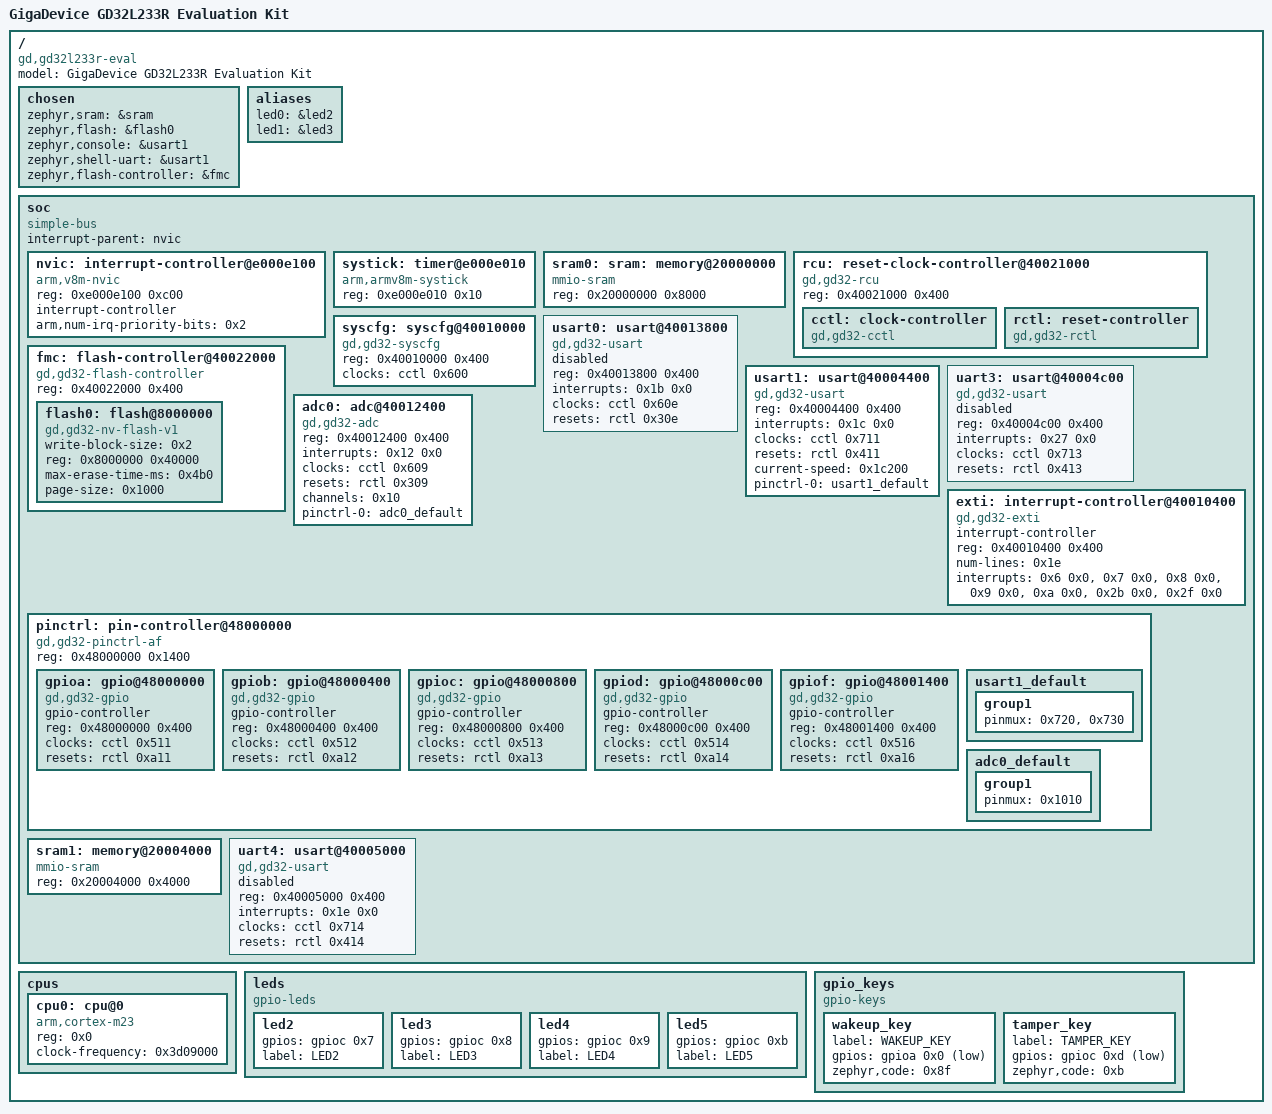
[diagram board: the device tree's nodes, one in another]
/dts-v1/;

/* node '/' defined in zephyr/dts/common/skeleton.dtsi:9 */
/ {
	#address-cells = < 0x1 >;                      /* in zephyr/dts/common/skeleton.dtsi:10 */
	#size-cells = < 0x1 >;                         /* in zephyr/dts/common/skeleton.dtsi:11 */
	model = "GigaDevice GD32L233R Evaluation Kit"; /* in zephyr/boards/gd/gd32l233r_eval/gd32l233r_eval.dts:13 */
	compatible = "gd,gd32l233r-eval";              /* in zephyr/boards/gd/gd32l233r_eval/gd32l233r_eval.dts:14 */

	/* node '/chosen' defined in zephyr/dts/common/skeleton.dtsi:13 */
	chosen {
		zephyr,sram = &sram;            /* in zephyr/boards/gd/gd32l233r_eval/gd32l233r_eval.dts:17 */
		zephyr,flash = &flash0;         /* in zephyr/boards/gd/gd32l233r_eval/gd32l233r_eval.dts:18 */
		zephyr,console = &usart1;       /* in zephyr/boards/gd/gd32l233r_eval/gd32l233r_eval.dts:19 */
		zephyr,shell-uart = &usart1;    /* in zephyr/boards/gd/gd32l233r_eval/gd32l233r_eval.dts:20 */
		zephyr,flash-controller = &fmc; /* in zephyr/boards/gd/gd32l233r_eval/gd32l233r_eval.dts:21 */
	};

	/* node '/aliases' defined in zephyr/dts/common/skeleton.dtsi:15 */
	aliases {
		led0 = &led2; /* in zephyr/boards/gd/gd32l233r_eval/gd32l233r_eval.dts:65 */
		led1 = &led3; /* in zephyr/boards/gd/gd32l233r_eval/gd32l233r_eval.dts:66 */
	};

	/* node '/soc' defined in zephyr/dts/arm/armv8-m.dtsi:6 */
	soc {
		#address-cells = < 0x1 >;     /* in zephyr/dts/arm/armv8-m.dtsi:7 */
		#size-cells = < 0x1 >;        /* in zephyr/dts/arm/armv8-m.dtsi:8 */
		compatible = "simple-bus";    /* in zephyr/dts/arm/armv8-m.dtsi:9 */
		interrupt-parent = < &nvic >; /* in zephyr/dts/arm/armv8-m.dtsi:10 */
		ranges;                       /* in zephyr/dts/arm/armv8-m.dtsi:11 */

		/* node '/soc/interrupt-controller@e000e100' defined in zephyr/dts/arm/armv8-m.dtsi:13 */
		nvic: interrupt-controller@e000e100 {
			#address-cells = < 0x1 >;            /* in zephyr/dts/arm/armv8-m.dtsi:14 */
			compatible = "arm,v8m-nvic";         /* in zephyr/dts/arm/armv8-m.dtsi:15 */
			reg = < 0xe000e100 0xc00 >;          /* in zephyr/dts/arm/armv8-m.dtsi:16 */
			interrupt-controller;                /* in zephyr/dts/arm/armv8-m.dtsi:17 */
			#interrupt-cells = < 0x2 >;          /* in zephyr/dts/arm/armv8-m.dtsi:18 */
			arm,num-irq-priority-bits = < 0x2 >; /* in zephyr/dts/arm/gd/gd32l23x/gd32l23x.dtsi:181 */
			phandle = < 0x1 >;                   /* in zephyr/dts/arm/armv8-m.dtsi:10 */
		};

		/* node '/soc/timer@e000e010' defined in zephyr/dts/arm/armv8-m.dtsi:21 */
		systick: timer@e000e010 {
			compatible = "arm,armv8m-systick"; /* in zephyr/dts/arm/armv8-m.dtsi:22 */
			reg = < 0xe000e010 0x10 >;         /* in zephyr/dts/arm/armv8-m.dtsi:23 */
		};

		/* node '/soc/memory@20000000' defined in zephyr/dts/arm/gd/gd32l23x/gd32l23x.dtsi:27 */
		sram0: sram: memory@20000000 {
			compatible = "mmio-sram";    /* in zephyr/dts/arm/gd/gd32l23x/gd32l233rc.dtsi:19 */
			reg = < 0x20000000 0x8000 >; /* in zephyr/dts/arm/gd/gd32l23x/gd32l233rc.dtsi:20 */
		};

		/* node '/soc/reset-clock-controller@40021000' defined in zephyr/dts/arm/gd/gd32l23x/gd32l23x.dtsi:32 */
		rcu: reset-clock-controller@40021000 {
			compatible = "gd,gd32-rcu"; /* in zephyr/dts/arm/gd/gd32l23x/gd32l23x.dtsi:33 */
			reg = < 0x40021000 0x400 >; /* in zephyr/dts/arm/gd/gd32l23x/gd32l23x.dtsi:34 */
			status = "okay";            /* in zephyr/dts/arm/gd/gd32l23x/gd32l23x.dtsi:35 */

			/* node '/soc/reset-clock-controller@40021000/clock-controller' defined in zephyr/dts/arm/gd/gd32l23x/gd32l23x.dtsi:37 */
			cctl: clock-controller {
				compatible = "gd,gd32-cctl"; /* in zephyr/dts/arm/gd/gd32l23x/gd32l23x.dtsi:38 */
				#clock-cells = < 0x1 >;      /* in zephyr/dts/arm/gd/gd32l23x/gd32l23x.dtsi:39 */
				status = "okay";             /* in zephyr/dts/arm/gd/gd32l23x/gd32l23x.dtsi:40 */
				phandle = < 0x2 >;           /* in zephyr/dts/arm/gd/gd32l23x/gd32l23x.dtsi:53 */
			};

			/* node '/soc/reset-clock-controller@40021000/reset-controller' defined in zephyr/dts/arm/gd/gd32l23x/gd32l23x.dtsi:43 */
			rctl: reset-controller {
				compatible = "gd,gd32-rctl"; /* in zephyr/dts/arm/gd/gd32l23x/gd32l23x.dtsi:44 */
				#reset-cells = < 0x1 >;      /* in zephyr/dts/arm/gd/gd32l23x/gd32l23x.dtsi:45 */
				status = "okay";             /* in zephyr/dts/arm/gd/gd32l23x/gd32l23x.dtsi:46 */
				phandle = < 0x3 >;           /* in zephyr/dts/arm/gd/gd32l23x/gd32l23x.dtsi:74 */
			};
		};

		/* node '/soc/syscfg@40010000' defined in zephyr/dts/arm/gd/gd32l23x/gd32l23x.dtsi:50 */
		syscfg: syscfg@40010000 {
			compatible = "gd,gd32-syscfg"; /* in zephyr/dts/arm/gd/gd32l23x/gd32l23x.dtsi:51 */
			reg = < 0x40010000 0x400 >;    /* in zephyr/dts/arm/gd/gd32l23x/gd32l23x.dtsi:52 */
			clocks = < &cctl 0x600 >;      /* in zephyr/dts/arm/gd/gd32l23x/gd32l23x.dtsi:53 */
		};

		/* node '/soc/flash-controller@40022000' defined in zephyr/dts/arm/gd/gd32l23x/gd32l23x.dtsi:56 */
		fmc: flash-controller@40022000 {
			compatible = "gd,gd32-flash-controller"; /* in zephyr/dts/arm/gd/gd32l23x/gd32l23x.dtsi:57 */
			reg = < 0x40022000 0x400 >;              /* in zephyr/dts/arm/gd/gd32l23x/gd32l23x.dtsi:58 */
			#address-cells = < 0x1 >;                /* in zephyr/dts/arm/gd/gd32l23x/gd32l23x.dtsi:60 */
			#size-cells = < 0x1 >;                   /* in zephyr/dts/arm/gd/gd32l23x/gd32l23x.dtsi:61 */

			/* node '/soc/flash-controller@40022000/flash@8000000' defined in zephyr/dts/arm/gd/gd32l23x/gd32l23x.dtsi:63 */
			flash0: flash@8000000 {
				compatible = "gd,gd32-nv-flash-v1",
				             "soc-nv-flash";        /* in zephyr/dts/arm/gd/gd32l23x/gd32l23x.dtsi:64 */
				write-block-size = < 0x2 >;         /* in zephyr/dts/arm/gd/gd32l23x/gd32l23x.dtsi:65 */
				reg = < 0x8000000 0x40000 >;        /* in zephyr/dts/arm/gd/gd32l23x/gd32l233rc.dtsi:35 */
				max-erase-time-ms = < 0x4b0 >;      /* in zephyr/dts/arm/gd/gd32l23x/gd32l233rc.dtsi:43 */
				page-size = < 0x1000 >;             /* in zephyr/dts/arm/gd/gd32l23x/gd32l233rc.dtsi:44 */
			};
		};

		/* node '/soc/usart@40013800' defined in zephyr/dts/arm/gd/gd32l23x/gd32l23x.dtsi:69 */
		usart0: usart@40013800 {
			compatible = "gd,gd32-usart"; /* in zephyr/dts/arm/gd/gd32l23x/gd32l23x.dtsi:70 */
			reg = < 0x40013800 0x400 >;   /* in zephyr/dts/arm/gd/gd32l23x/gd32l23x.dtsi:71 */
			interrupts = < 0x1b 0x0 >;    /* in zephyr/dts/arm/gd/gd32l23x/gd32l23x.dtsi:72 */
			clocks = < &cctl 0x60e >;     /* in zephyr/dts/arm/gd/gd32l23x/gd32l23x.dtsi:73 */
			resets = < &rctl 0x30e >;     /* in zephyr/dts/arm/gd/gd32l23x/gd32l23x.dtsi:74 */
			status = "disabled";          /* in zephyr/dts/arm/gd/gd32l23x/gd32l23x.dtsi:75 */
		};

		/* node '/soc/usart@40004400' defined in zephyr/dts/arm/gd/gd32l23x/gd32l23x.dtsi:78 */
		usart1: usart@40004400 {
			compatible = "gd,gd32-usart";    /* in zephyr/dts/arm/gd/gd32l23x/gd32l23x.dtsi:79 */
			reg = < 0x40004400 0x400 >;      /* in zephyr/dts/arm/gd/gd32l23x/gd32l23x.dtsi:80 */
			interrupts = < 0x1c 0x0 >;       /* in zephyr/dts/arm/gd/gd32l23x/gd32l23x.dtsi:81 */
			clocks = < &cctl 0x711 >;        /* in zephyr/dts/arm/gd/gd32l23x/gd32l23x.dtsi:82 */
			resets = < &rctl 0x411 >;        /* in zephyr/dts/arm/gd/gd32l23x/gd32l23x.dtsi:83 */
			status = "okay";                 /* in zephyr/boards/gd/gd32l233r_eval/gd32l233r_eval.dts:91 */
			current-speed = < 0x1c200 >;     /* in zephyr/boards/gd/gd32l233r_eval/gd32l233r_eval.dts:92 */
			pinctrl-0 = < &usart1_default >; /* in zephyr/boards/gd/gd32l233r_eval/gd32l233r_eval.dts:93 */
			pinctrl-names = "default";       /* in zephyr/boards/gd/gd32l233r_eval/gd32l233r_eval.dts:94 */
		};

		/* node '/soc/usart@40004c00' defined in zephyr/dts/arm/gd/gd32l23x/gd32l23x.dtsi:87 */
		uart3: usart@40004c00 {
			compatible = "gd,gd32-usart"; /* in zephyr/dts/arm/gd/gd32l23x/gd32l23x.dtsi:88 */
			reg = < 0x40004c00 0x400 >;   /* in zephyr/dts/arm/gd/gd32l23x/gd32l23x.dtsi:89 */
			interrupts = < 0x27 0x0 >;    /* in zephyr/dts/arm/gd/gd32l23x/gd32l23x.dtsi:90 */
			clocks = < &cctl 0x713 >;     /* in zephyr/dts/arm/gd/gd32l23x/gd32l23x.dtsi:91 */
			resets = < &rctl 0x413 >;     /* in zephyr/dts/arm/gd/gd32l23x/gd32l23x.dtsi:92 */
			status = "disabled";          /* in zephyr/dts/arm/gd/gd32l23x/gd32l23x.dtsi:93 */
		};

		/* node '/soc/adc@40012400' defined in zephyr/dts/arm/gd/gd32l23x/gd32l23x.dtsi:96 */
		adc0: adc@40012400 {
			compatible = "gd,gd32-adc";    /* in zephyr/dts/arm/gd/gd32l23x/gd32l23x.dtsi:97 */
			reg = < 0x40012400 0x400 >;    /* in zephyr/dts/arm/gd/gd32l23x/gd32l23x.dtsi:98 */
			interrupts = < 0x12 0x0 >;     /* in zephyr/dts/arm/gd/gd32l23x/gd32l23x.dtsi:99 */
			clocks = < &cctl 0x609 >;      /* in zephyr/dts/arm/gd/gd32l23x/gd32l23x.dtsi:100 */
			resets = < &rctl 0x309 >;      /* in zephyr/dts/arm/gd/gd32l23x/gd32l23x.dtsi:101 */
			channels = < 0x10 >;           /* in zephyr/dts/arm/gd/gd32l23x/gd32l23x.dtsi:102 */
			#io-channel-cells = < 0x1 >;   /* in zephyr/dts/arm/gd/gd32l23x/gd32l23x.dtsi:104 */
			status = "okay";               /* in zephyr/boards/gd/gd32l233r_eval/gd32l233r_eval.dts:98 */
			pinctrl-0 = < &adc0_default >; /* in zephyr/boards/gd/gd32l233r_eval/gd32l233r_eval.dts:99 */
			pinctrl-names = "default";     /* in zephyr/boards/gd/gd32l233r_eval/gd32l233r_eval.dts:100 */
		};

		/* node '/soc/interrupt-controller@40010400' defined in zephyr/dts/arm/gd/gd32l23x/gd32l23x.dtsi:107 */
		exti: interrupt-controller@40010400 {
			compatible = "gd,gd32-exti";   /* in zephyr/dts/arm/gd/gd32l23x/gd32l23x.dtsi:108 */
			interrupt-controller;          /* in zephyr/dts/arm/gd/gd32l23x/gd32l23x.dtsi:109 */
			#interrupt-cells = < 0x1 >;    /* in zephyr/dts/arm/gd/gd32l23x/gd32l23x.dtsi:110 */
			reg = < 0x40010400 0x400 >;    /* in zephyr/dts/arm/gd/gd32l23x/gd32l23x.dtsi:111 */
			num-lines = < 0x1e >;          /* in zephyr/dts/arm/gd/gd32l23x/gd32l23x.dtsi:112 */
			interrupts = < 0x6 0x0 >,
			             < 0x7 0x0 >,
			             < 0x8 0x0 >,
			             < 0x9 0x0 >,
			             < 0xa 0x0 >,
			             < 0x2b 0x0 >,
			             < 0x2f 0x0 >;     /* in zephyr/dts/arm/gd/gd32l23x/gd32l23x.dtsi:113 */
			interrupt-names = "line0",
			                  "line1",
			                  "line2",
			                  "line3",
			                  "line4",
			                  "line5-9",
			                  "line10-15"; /* in zephyr/dts/arm/gd/gd32l23x/gd32l23x.dtsi:115 */
			status = "okay";               /* in zephyr/dts/arm/gd/gd32l23x/gd32l23x.dtsi:117 */
		};

		/* node '/soc/pin-controller@48000000' defined in zephyr/dts/arm/gd/gd32l23x/gd32l23x.dtsi:120 */
		pinctrl: pin-controller@48000000 {
			compatible = "gd,gd32-pinctrl-af"; /* in zephyr/dts/arm/gd/gd32l23x/gd32l23x.dtsi:121 */
			reg = < 0x48000000 0x1400 >;       /* in zephyr/dts/arm/gd/gd32l23x/gd32l23x.dtsi:122 */
			#address-cells = < 0x1 >;          /* in zephyr/dts/arm/gd/gd32l23x/gd32l23x.dtsi:123 */
			#size-cells = < 0x1 >;             /* in zephyr/dts/arm/gd/gd32l23x/gd32l23x.dtsi:124 */
			status = "okay";                   /* in zephyr/dts/arm/gd/gd32l23x/gd32l23x.dtsi:125 */

			/* node '/soc/pin-controller@48000000/gpio@48000000' defined in zephyr/dts/arm/gd/gd32l23x/gd32l23x.dtsi:127 */
			gpioa: gpio@48000000 {
				compatible = "gd,gd32-gpio"; /* in zephyr/dts/arm/gd/gd32l23x/gd32l23x.dtsi:128 */
				gpio-controller;             /* in zephyr/dts/arm/gd/gd32l23x/gd32l23x.dtsi:129 */
				#gpio-cells = < 0x2 >;       /* in zephyr/dts/arm/gd/gd32l23x/gd32l23x.dtsi:130 */
				reg = < 0x48000000 0x400 >;  /* in zephyr/dts/arm/gd/gd32l23x/gd32l23x.dtsi:131 */
				clocks = < &cctl 0x511 >;    /* in zephyr/dts/arm/gd/gd32l23x/gd32l23x.dtsi:132 */
				resets = < &rctl 0xa11 >;    /* in zephyr/dts/arm/gd/gd32l23x/gd32l23x.dtsi:133 */
				status = "okay";             /* in zephyr/boards/gd/gd32l233r_eval/gd32l233r_eval.dts:71 */
				phandle = < 0x7 >;           /* in zephyr/boards/gd/gd32l233r_eval/gd32l233r_eval.dts:53 */
			};

			/* node '/soc/pin-controller@48000000/gpio@48000400' defined in zephyr/dts/arm/gd/gd32l23x/gd32l23x.dtsi:137 */
			gpiob: gpio@48000400 {
				compatible = "gd,gd32-gpio"; /* in zephyr/dts/arm/gd/gd32l23x/gd32l23x.dtsi:138 */
				gpio-controller;             /* in zephyr/dts/arm/gd/gd32l23x/gd32l23x.dtsi:139 */
				#gpio-cells = < 0x2 >;       /* in zephyr/dts/arm/gd/gd32l23x/gd32l23x.dtsi:140 */
				reg = < 0x48000400 0x400 >;  /* in zephyr/dts/arm/gd/gd32l23x/gd32l23x.dtsi:141 */
				clocks = < &cctl 0x512 >;    /* in zephyr/dts/arm/gd/gd32l23x/gd32l23x.dtsi:142 */
				resets = < &rctl 0xa12 >;    /* in zephyr/dts/arm/gd/gd32l23x/gd32l23x.dtsi:143 */
				status = "okay";             /* in zephyr/boards/gd/gd32l233r_eval/gd32l233r_eval.dts:75 */
			};

			/* node '/soc/pin-controller@48000000/gpio@48000800' defined in zephyr/dts/arm/gd/gd32l23x/gd32l23x.dtsi:147 */
			gpioc: gpio@48000800 {
				compatible = "gd,gd32-gpio"; /* in zephyr/dts/arm/gd/gd32l23x/gd32l23x.dtsi:148 */
				gpio-controller;             /* in zephyr/dts/arm/gd/gd32l23x/gd32l23x.dtsi:149 */
				#gpio-cells = < 0x2 >;       /* in zephyr/dts/arm/gd/gd32l23x/gd32l23x.dtsi:150 */
				reg = < 0x48000800 0x400 >;  /* in zephyr/dts/arm/gd/gd32l23x/gd32l23x.dtsi:151 */
				clocks = < &cctl 0x513 >;    /* in zephyr/dts/arm/gd/gd32l23x/gd32l23x.dtsi:152 */
				resets = < &rctl 0xa13 >;    /* in zephyr/dts/arm/gd/gd32l23x/gd32l23x.dtsi:153 */
				status = "okay";             /* in zephyr/boards/gd/gd32l233r_eval/gd32l233r_eval.dts:79 */
				phandle = < 0x6 >;           /* in zephyr/boards/gd/gd32l233r_eval/gd32l233r_eval.dts:28 */
			};

			/* node '/soc/pin-controller@48000000/gpio@48000c00' defined in zephyr/dts/arm/gd/gd32l23x/gd32l23x.dtsi:157 */
			gpiod: gpio@48000c00 {
				compatible = "gd,gd32-gpio"; /* in zephyr/dts/arm/gd/gd32l23x/gd32l23x.dtsi:158 */
				gpio-controller;             /* in zephyr/dts/arm/gd/gd32l23x/gd32l23x.dtsi:159 */
				#gpio-cells = < 0x2 >;       /* in zephyr/dts/arm/gd/gd32l23x/gd32l23x.dtsi:160 */
				reg = < 0x48000c00 0x400 >;  /* in zephyr/dts/arm/gd/gd32l23x/gd32l23x.dtsi:161 */
				clocks = < &cctl 0x514 >;    /* in zephyr/dts/arm/gd/gd32l23x/gd32l23x.dtsi:162 */
				resets = < &rctl 0xa14 >;    /* in zephyr/dts/arm/gd/gd32l23x/gd32l23x.dtsi:163 */
				status = "okay";             /* in zephyr/boards/gd/gd32l233r_eval/gd32l233r_eval.dts:83 */
			};

			/* node '/soc/pin-controller@48000000/gpio@48001400' defined in zephyr/dts/arm/gd/gd32l23x/gd32l23x.dtsi:167 */
			gpiof: gpio@48001400 {
				compatible = "gd,gd32-gpio"; /* in zephyr/dts/arm/gd/gd32l23x/gd32l23x.dtsi:168 */
				gpio-controller;             /* in zephyr/dts/arm/gd/gd32l23x/gd32l23x.dtsi:169 */
				#gpio-cells = < 0x2 >;       /* in zephyr/dts/arm/gd/gd32l23x/gd32l23x.dtsi:170 */
				reg = < 0x48001400 0x400 >;  /* in zephyr/dts/arm/gd/gd32l23x/gd32l23x.dtsi:171 */
				clocks = < &cctl 0x516 >;    /* in zephyr/dts/arm/gd/gd32l23x/gd32l23x.dtsi:172 */
				resets = < &rctl 0xa16 >;    /* in zephyr/dts/arm/gd/gd32l23x/gd32l23x.dtsi:173 */
				status = "okay";             /* in zephyr/boards/gd/gd32l233r_eval/gd32l233r_eval.dts:87 */
			};

			/* node '/soc/pin-controller@48000000/usart1_default' defined in zephyr/boards/gd/gd32l233r_eval/gd32l233r_eval-pinctrl.dtsi:9 */
			usart1_default: usart1_default {
				phandle = < 0x4 >; /* in zephyr/boards/gd/gd32l233r_eval/gd32l233r_eval.dts:93 */

				/* node '/soc/pin-controller@48000000/usart1_default/group1' defined in zephyr/boards/gd/gd32l233r_eval/gd32l233r_eval-pinctrl.dtsi:10 */
				group1 {
					pinmux = < 0x720 >,
					         < 0x730 >; /* in zephyr/boards/gd/gd32l233r_eval/gd32l233r_eval-pinctrl.dtsi:11 */
				};
			};

			/* node '/soc/pin-controller@48000000/adc0_default' defined in zephyr/boards/gd/gd32l233r_eval/gd32l233r_eval-pinctrl.dtsi:15 */
			adc0_default: adc0_default {
				phandle = < 0x5 >; /* in zephyr/boards/gd/gd32l233r_eval/gd32l233r_eval.dts:99 */

				/* node '/soc/pin-controller@48000000/adc0_default/group1' defined in zephyr/boards/gd/gd32l233r_eval/gd32l233r_eval-pinctrl.dtsi:16 */
				group1 {
					pinmux = < 0x1010 >; /* in zephyr/boards/gd/gd32l233r_eval/gd32l233r_eval-pinctrl.dtsi:17 */
				};
			};
		};

		/* node '/soc/memory@20004000' defined in zephyr/dts/arm/gd/gd32l23x/gd32l233rc.dtsi:12 */
		sram1: memory@20004000 {
			compatible = "mmio-sram";    /* in zephyr/dts/arm/gd/gd32l23x/gd32l233rc.dtsi:13 */
			reg = < 0x20004000 0x4000 >; /* in zephyr/dts/arm/gd/gd32l23x/gd32l233rc.dtsi:14 */
		};

		/* node '/soc/usart@40005000' defined in zephyr/dts/arm/gd/gd32l23x/gd32l233rc.dtsi:23 */
		uart4: usart@40005000 {
			compatible = "gd,gd32-usart"; /* in zephyr/dts/arm/gd/gd32l23x/gd32l233rc.dtsi:24 */
			reg = < 0x40005000 0x400 >;   /* in zephyr/dts/arm/gd/gd32l23x/gd32l233rc.dtsi:25 */
			interrupts = < 0x1e 0x0 >;    /* in zephyr/dts/arm/gd/gd32l23x/gd32l233rc.dtsi:26 */
			clocks = < &cctl 0x714 >;     /* in zephyr/dts/arm/gd/gd32l23x/gd32l233rc.dtsi:27 */
			resets = < &rctl 0x414 >;     /* in zephyr/dts/arm/gd/gd32l23x/gd32l233rc.dtsi:28 */
			status = "disabled";          /* in zephyr/dts/arm/gd/gd32l23x/gd32l233rc.dtsi:29 */
		};
	};

	/* node '/cpus' defined in zephyr/dts/arm/gd/gd32l23x/gd32l23x.dtsi:15 */
	cpus {
		#address-cells = < 0x1 >; /* in zephyr/dts/arm/gd/gd32l23x/gd32l23x.dtsi:16 */
		#size-cells = < 0x0 >;    /* in zephyr/dts/arm/gd/gd32l23x/gd32l23x.dtsi:17 */

		/* node '/cpus/cpu@0' defined in zephyr/dts/arm/gd/gd32l23x/gd32l23x.dtsi:19 */
		cpu0: cpu@0 {
			compatible = "arm,cortex-m23";   /* in zephyr/dts/arm/gd/gd32l23x/gd32l23x.dtsi:20 */
			reg = < 0x0 >;                   /* in zephyr/dts/arm/gd/gd32l23x/gd32l23x.dtsi:21 */
			clock-frequency = < 0x3d09000 >; /* in zephyr/dts/arm/gd/gd32l23x/gd32l23x.dtsi:22 */
		};
	};

	/* node '/leds' defined in zephyr/boards/gd/gd32l233r_eval/gd32l233r_eval.dts:24 */
	leds {
		compatible = "gpio-leds"; /* in zephyr/boards/gd/gd32l233r_eval/gd32l233r_eval.dts:25 */

		/* node '/leds/led2' defined in zephyr/boards/gd/gd32l233r_eval/gd32l233r_eval.dts:27 */
		led2: led2 {
			gpios = < &gpioc 0x7 0x0 >; /* in zephyr/boards/gd/gd32l233r_eval/gd32l233r_eval.dts:28 */
			label = "LED2";             /* in zephyr/boards/gd/gd32l233r_eval/gd32l233r_eval.dts:29 */
		};

		/* node '/leds/led3' defined in zephyr/boards/gd/gd32l233r_eval/gd32l233r_eval.dts:32 */
		led3: led3 {
			gpios = < &gpioc 0x8 0x0 >; /* in zephyr/boards/gd/gd32l233r_eval/gd32l233r_eval.dts:33 */
			label = "LED3";             /* in zephyr/boards/gd/gd32l233r_eval/gd32l233r_eval.dts:34 */
		};

		/* node '/leds/led4' defined in zephyr/boards/gd/gd32l233r_eval/gd32l233r_eval.dts:37 */
		led4: led4 {
			gpios = < &gpioc 0x9 0x0 >; /* in zephyr/boards/gd/gd32l233r_eval/gd32l233r_eval.dts:38 */
			label = "LED4";             /* in zephyr/boards/gd/gd32l233r_eval/gd32l233r_eval.dts:39 */
		};

		/* node '/leds/led5' defined in zephyr/boards/gd/gd32l233r_eval/gd32l233r_eval.dts:42 */
		led5: led5 {
			gpios = < &gpioc 0xb 0x0 >; /* in zephyr/boards/gd/gd32l233r_eval/gd32l233r_eval.dts:43 */
			label = "LED5";             /* in zephyr/boards/gd/gd32l233r_eval/gd32l233r_eval.dts:44 */
		};
	};

	/* node '/gpio_keys' defined in zephyr/boards/gd/gd32l233r_eval/gd32l233r_eval.dts:48 */
	gpio_keys {
		compatible = "gpio-keys"; /* in zephyr/boards/gd/gd32l233r_eval/gd32l233r_eval.dts:49 */

		/* node '/gpio_keys/wakeup_key' defined in zephyr/boards/gd/gd32l233r_eval/gd32l233r_eval.dts:51 */
		wakeup_key: wakeup_key {
			label = "WAKEUP_KEY";       /* in zephyr/boards/gd/gd32l233r_eval/gd32l233r_eval.dts:52 */
			gpios = < &gpioa 0x0 0x1 >; /* in zephyr/boards/gd/gd32l233r_eval/gd32l233r_eval.dts:53 */
			zephyr,code = < 0x8f >;     /* in zephyr/boards/gd/gd32l233r_eval/gd32l233r_eval.dts:54 */
		};

		/* node '/gpio_keys/tamper_key' defined in zephyr/boards/gd/gd32l233r_eval/gd32l233r_eval.dts:57 */
		tamper_key: tamper_key {
			label = "TAMPER_KEY";       /* in zephyr/boards/gd/gd32l233r_eval/gd32l233r_eval.dts:58 */
			gpios = < &gpioc 0xd 0x1 >; /* in zephyr/boards/gd/gd32l233r_eval/gd32l233r_eval.dts:59 */
			zephyr,code = < 0xb >;      /* in zephyr/boards/gd/gd32l233r_eval/gd32l233r_eval.dts:60 */
		};
	};
};
